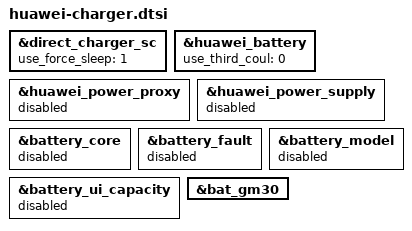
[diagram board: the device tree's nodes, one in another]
#include "../huawei_charger/mt6853_hjc_huawei_charger.dtsi"

&direct_charger_sc {
	use_force_sleep = <1>;
};

&huawei_battery {
	use_third_coul = <0>;
};

&huawei_power_proxy  {
	status = "disabled";
};
&huawei_power_supply {
	status = "disabled";
};
&battery_core {
	status = "disabled";
};
&battery_fault {
	status = "disabled";
};
&battery_model {
	status = "disabled";
};
&battery_ui_capacity {
	status = "disabled";
};

&bat_gm30 {
	status = "ok";
};
